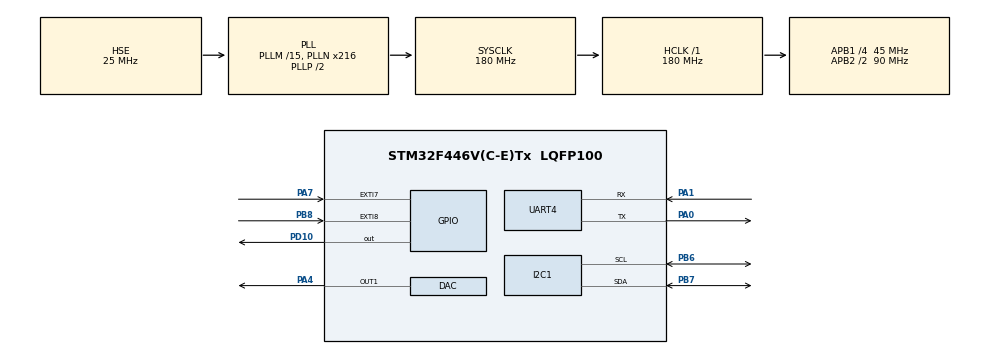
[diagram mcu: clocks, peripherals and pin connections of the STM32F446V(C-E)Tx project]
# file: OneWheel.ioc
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Dma.I2C1_RX.0.Direction=DMA_PERIPH_TO_MEMORY
Dma.I2C1_RX.0.FIFOMode=DMA_FIFOMODE_DISABLE
Dma.I2C1_RX.0.Instance=DMA1_Stream0
Dma.I2C1_RX.0.MemDataAlignment=DMA_MDATAALIGN_BYTE
Dma.I2C1_RX.0.MemInc=DMA_MINC_ENABLE
Dma.I2C1_RX.0.Mode=DMA_CIRCULAR
Dma.I2C1_RX.0.PeriphDataAlignment=DMA_PDATAALIGN_BYTE
Dma.I2C1_RX.0.PeriphInc=DMA_PINC_DISABLE
Dma.I2C1_RX.0.Priority=DMA_PRIORITY_LOW
Dma.Request0=I2C1_RX
I2C1.I2C_Mode=I2C_Fast
Mcu.Family=STM32F4
Mcu.Name=STM32F446V(C-E)Tx
Mcu.Package=LQFP100
NVIC.DMA1_Stream0_IRQn=true\:0\:0\:false\:false\:true\:false\:true
NVIC.EXTI9_5_IRQn=true\:0\:0\:false\:false\:true\:true\:true
NVIC.I2C1_EV_IRQn=true\:0\:0\:false\:false\:true\:true\:true
NVIC.PriorityGroup=NVIC_PRIORITYGROUP_4
PA0-WKUP.Mode=Asynchronous
PA0-WKUP.Signal=UART4_TX
PA1.Mode=Asynchronous
PA1.Signal=UART4_RX
PA4.Signal=COMP_DAC1_group
PA7.Signal=GPXTI7
PB6.Mode=I2C
PB6.Signal=I2C1_SCL
PB7.Mode=I2C
PB7.Signal=I2C1_SDA
PB8.GPIO_PuPd=GPIO_PULLDOWN
PB8.Signal=GPXTI8
PD10.Signal=GPIO_Output
PH0-OSC_IN.Mode=HSE-External-Oscillator
PH0-OSC_IN.Signal=RCC_OSC_IN
PH1-OSC_OUT.Mode=HSE-External-Oscillator
PH1-OSC_OUT.Signal=RCC_OSC_OUT
ProjectManager.HeapSize=0x200
ProjectManager.StackSize=0x400
ProjectManager.TargetToolchain=MDK-ARM V5.27
RCC.AHBFreq_Value=180000000
RCC.APB1CLKDivider=RCC_HCLK_DIV4
RCC.APB1Freq_Value=45000000
RCC.APB1TimFreq_Value=90000000
RCC.APB2CLKDivider=RCC_HCLK_DIV2
RCC.APB2Freq_Value=90000000
RCC.APB2TimFreq_Value=180000000
RCC.CortexFreq_Value=180000000
RCC.HCLKFreq_Value=180000000
RCC.PLLM=15
RCC.PLLN=216
RCC.PLLSourceVirtual=RCC_PLLSOURCE_HSE
RCC.SYSCLKFreq_VALUE=180000000
RCC.SYSCLKSource=RCC_SYSCLKSOURCE_PLLCLK
RCC.USBFreq_Value=180000000
RCC.VCOOutputFreq_Value=360000000
SH.COMP_DAC1_group.0=DAC_OUT1,DAC_OUT1
UART4.VirtualMode=Asynchronous
board=custom

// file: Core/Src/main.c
/* USER CODE BEGIN Header */
/**
  ******************************************************************************
  * @file           : main.c
  * @brief          : Main program body
  ******************************************************************************
  * @attention
  *
  * <h2><center>&copy; Copyright (c) 2021 STMicroelectronics.
  * All rights reserved.</center></h2>
  *
  * This software component is licensed by ST under BSD 3-Clause license,
  * the "License"; You may not use this file except in compliance with the
  * License. You may obtain a copy of the License at:
  *                        opensource.org/licenses/BSD-3-Clause
  *
  ******************************************************************************
  */
/* USER CODE END Header */
#include "main.h"
#include "dac.h"
#include "dma.h"
#include "i2c.h"
#include "usart.h"
#include "gpio.h"

#include "I2Cdev.h"

#include "MPU6050_6Axis_MotionApps_V6_12.h"

void SystemClock_Config(void);

/* USER CODE BEGIN 0 */

	uint8_t BootHeader[] ={"Booted"};

	//MPU6050_t boardGyro;
  uint8_t Rec_Data[14];
	uint8_t gyroFlag=0;

//const uint16_t i2c_timeout = 100;
/* USER CODE END 0 */

int main(void)
{

  /* MCU Configuration--------------------------------------------------------*/

  /* Reset of all peripherals, Initializes the Flash interface and the Systick. */
  HAL_Init();

  /* Configure the system clock */
  SystemClock_Config();

  /* Initialize all configured peripherals */
  MX_GPIO_Init();
  MX_DMA_Init();
  MX_I2C1_Init();
  MX_UART4_Init();
  MX_DAC_Init();
  /* USER CODE BEGIN 2 */

	//while (MPU6050_Init(&hi2c1) == 1);
	HAL_UART_Transmit(&huart4,BootHeader,sizeof(BootHeader),1000);

	//HAL_I2C_Mem_Read_DMA
	//HAL_I2C_Master_Receive_DMA
	//HAL_I2C_Master_Receive_DMA(&hi2c1,MPU6050_ADDR, ACCEL_XOUT_H_REG, 1, Rec_Data, 6, i2c_timeout);
  /* USER CODE END 2 */

  /* Infinite loop */
  while (1)
  {

  }
}

void SystemClock_Config(void)
{
  RCC_OscInitTypeDef RCC_OscInitStruct = {0};
  RCC_ClkInitTypeDef RCC_ClkInitStruct = {0};

  /** Configure the main internal regulator output voltage
  */
  __HAL_RCC_PWR_CLK_ENABLE();
  __HAL_PWR_VOLTAGESCALING_CONFIG(PWR_REGULATOR_VOLTAGE_SCALE1);
  /** Initializes the RCC Oscillators according to the specified parameters
  * in the RCC_OscInitTypeDef structure.
  */
  RCC_OscInitStruct.OscillatorType = RCC_OSCILLATORTYPE_HSE;
  RCC_OscInitStruct.HSEState = RCC_HSE_ON;
  RCC_OscInitStruct.PLL.PLLState = RCC_PLL_ON;
  RCC_OscInitStruct.PLL.PLLSource = RCC_PLLSOURCE_HSE;
  RCC_OscInitStruct.PLL.PLLM = 15;
  RCC_OscInitStruct.PLL.PLLN = 216;
  RCC_OscInitStruct.PLL.PLLP = RCC_PLLP_DIV2;
  RCC_OscInitStruct.PLL.PLLQ = 2;
  RCC_OscInitStruct.PLL.PLLR = 2;
  if (HAL_RCC_OscConfig(&RCC_OscInitStruct) != HAL_OK)
  {
    Error_Handler();
  }
  /** Activate the Over-Drive mode
  */
  if (HAL_PWREx_EnableOverDrive() != HAL_OK)
  {
    Error_Handler();
  }
  /** Initializes the CPU, AHB and APB buses clocks
  */
  RCC_ClkInitStruct.ClockType = RCC_CLOCKTYPE_HCLK|RCC_CLOCKTYPE_SYSCLK
                              |RCC_CLOCKTYPE_PCLK1|RCC_CLOCKTYPE_PCLK2;
  RCC_ClkInitStruct.SYSCLKSource = RCC_SYSCLKSOURCE_PLLCLK;
  RCC_ClkInitStruct.AHBCLKDivider = RCC_SYSCLK_DIV1;
  RCC_ClkInitStruct.APB1CLKDivider = RCC_HCLK_DIV4;
  RCC_ClkInitStruct.APB2CLKDivider = RCC_HCLK_DIV2;

  if (HAL_RCC_ClockConfig(&RCC_ClkInitStruct, FLASH_LATENCY_5) != HAL_OK)
  {
    Error_Handler();
  }
}

/* USER CODE BEGIN 4 */

void HAL_GPIO_EXTI_Callback(uint16_t GPIO_Pin)
{
	if(GPIO_Pin == GPIO_PIN_8)
	{
		HAL_GPIO_WritePin(GPIOD, GPIO_PIN_10, GPIO_PIN_SET);
		//HAL_I2C_Master_Receive(&hi2c1,MPU6050_ADDR,Rec_Data,14,i2c_timeout);
		//MPU6050_Read_All(&hi2c1,&boardGyro);
		//HAL_I2C_Master_Receive(I2C_HandleTypeDef *hi2c, uint16_t DevAddress, uint8_t *pData, uint16_t Size, uint32_t Timeout);
		//HAL_I2C_Slave_Receive(I2C_HandleTypeDef *hi2c, uint8_t *pData, uint16_t Size, uint32_t Timeout);

		HAL_GPIO_WritePin(GPIOD, GPIO_PIN_10, GPIO_PIN_RESET);
    //HAL_I2C_Mem_Read(I2Cx, MPU6050_ADDR, ACCEL_XOUT_H_REG, 1, Rec_Data, 14, i2c_timeout);
	}

}
/* USER CODE END 4 */

void Error_Handler(void)
{
  __disable_irq();
  while (1)
  {
  }
}

/************************ (C) COPYRIGHT STMicroelectronics *****END OF FILE****/
